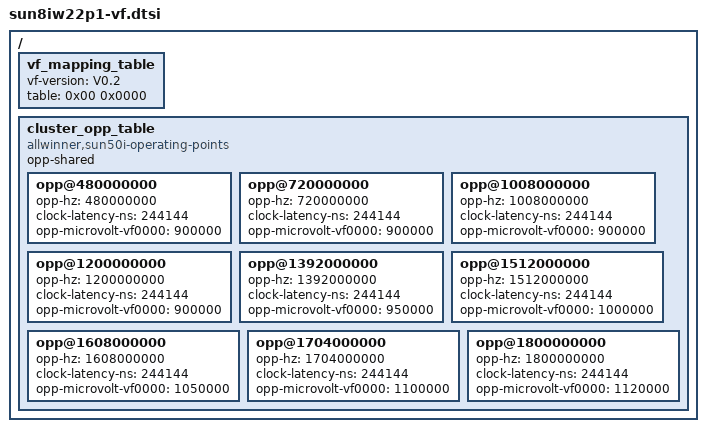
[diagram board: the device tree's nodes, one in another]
/* SPDX-License-Identifier: GPL-2.0-or-later */
/{
	vf_mapping_table: vf_mapping_table {
		vf-version = "V0.2";
		table = <
			0x00 0x0000
			>;
	};

	cluster_opp_table: cluster_opp_table {
		compatible = "allwinner,sun50i-operating-points";
		opp-shared;

		opp@480000000 {
			opp-hz = /bits/ 64 <480000000>;
			clock-latency-ns = <244144>; /* 8 32k periods */
			opp-microvolt-vf0000 = <900000>;
		};

		opp@720000000 {
			opp-hz = /bits/ 64 <720000000>;
			clock-latency-ns = <244144>; /* 8 32k periods */
			opp-microvolt-vf0000 = <900000>;
		};

		opp@1008000000 {
			opp-hz = /bits/ 64 <1008000000>;
			clock-latency-ns = <244144>; /* 8 32k periods */
			opp-microvolt-vf0000 = <900000>;
		};

		opp@1200000000 {
			opp-hz = /bits/ 64 <1200000000>;
			clock-latency-ns = <244144>; /* 8 32k periods */
			opp-microvolt-vf0000 = <900000>;
		};

		opp@1392000000 {
			opp-hz = /bits/ 64 <1392000000>;
			clock-latency-ns = <244144>; /* 8 32k periods */
			opp-microvolt-vf0000 = <950000>;
		};

		opp@1512000000 {
			opp-hz = /bits/ 64 <1512000000>;
			clock-latency-ns = <244144>; /* 8 32k periods */
			opp-microvolt-vf0000 = <1000000>;
		};

		opp@1608000000 {
			opp-hz = /bits/ 64 <1608000000>;
			clock-latency-ns = <244144>; /* 8 32k periods */
			opp-microvolt-vf0000 = <1050000>;
		};

		opp@1704000000 {
			opp-hz = /bits/ 64 <1704000000>;
			clock-latency-ns = <244144>; /* 8 32k periods */
			opp-microvolt-vf0000 = <1100000>;
		};

		opp@1800000000 {
			opp-hz = /bits/ 64 <1800000000>;
			clock-latency-ns = <244144>; /* 8 32k periods */
			opp-microvolt-vf0000 = <1120000>;
		};
	};
};
